# STM32U083xx register map
File version: 1.0
Registers are 32-bit, read-write, reset 0x0 unless marked. A register's access mark holds for its fields unless they carry their own. Offsets are from the block's base; [hi:lo] are bit positions; {n}, {i} and the like mark numbered series.

## LPTIM1 — LPTIMER
Base 0x40007C00
Same registers: LPTIM3 0x40009000, LPTIM2 0x40009400
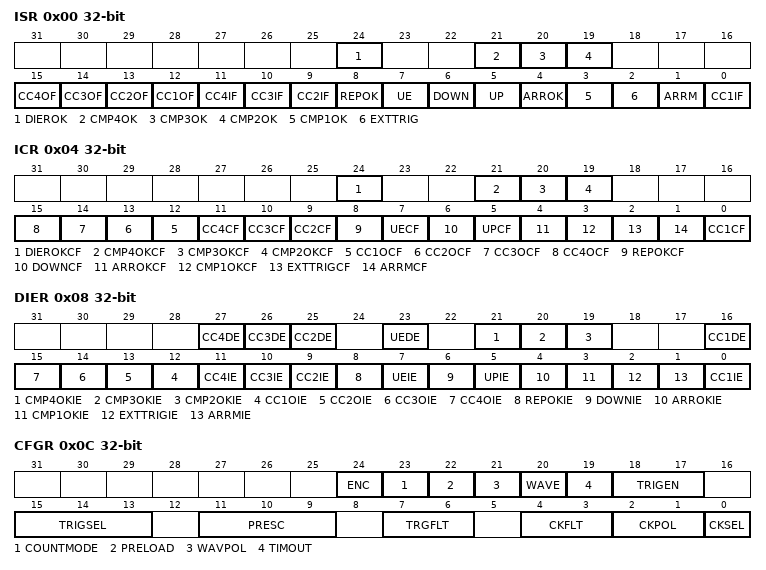
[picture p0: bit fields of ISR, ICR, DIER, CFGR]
0x00 ISR — LPTIM Interrupt and Status register
  [24] DIEROK — DMA & interrupt enable update OK
  [21] CMP4OK — Compare register 4 update OK
  [20] CMP3OK — Compare register 3 update OK
  [19] CMP2OK — Compare register 2 update OK
  [n+11] CC{n}OF (n=1..4) — Capture/Compare {n} over-capture flag
  [11] CC4IF — Capture/Compare 4 interrupt flag
  [10] CC3IF — Capture/Compare 3 interrupt flag
  [9] CC2IF — Capture/Compare 2 interrupt flag
  [8] REPOK — Repetition register update OK
  [7] UE — Update event
  [6] DOWN — Counter direction change up to down
  [5] UP — Counter direction change down to up
  [4] ARROK — Autoreload register update OK
  [3] CMP1OK — Compare register 1 update OK
  [2] EXTTRIG — External trigger edge event
  [1] ARRM — Autoreload match
  [0] CC1IF — Capture/Compare 1 interrupt flag
0x04 ICR — LPTIM Interrupt Clear register
  [24] DIEROKCF — DMA & interrupt enable update OK clear flag
  [21] CMP4OKCF — Compare register 4 update OK clear flag
  [20] CMP3OKCF — Compare register 3 update OK clear flag
  [19] CMP2OKCF — Compare register 2 update OK clear flag
  [n+11] CC{n}OCF (n=1..4) — Capture/Compare {n} over-capture clear flag
  [11] CC4CF — Capture/Compare 4 clear flag
  [10] CC3CF — Capture/Compare 3 clear flag
  [9] CC2CF — Capture/Compare 2 clear flag
  [8] REPOKCF — Repetition register update OK clear flag
  [7] UECF — Update event clear flag
  [6] DOWNCF — Counter direction change up to down clear flag
  [5] UPCF — Counter direction change down to up clear flag
  [4] ARROKCF — Autoreload register update OK clear flag
  [3] CMP1OKCF — Compare register 1 update OK clear flag
  [2] EXTTRIGCF — External trigger edge event clear flag
  [1] ARRMCF — Autoreload match clear flag
  [0] CC1CF — Capture/Compare 1 clear flag
0x08 DIER — LPTIM Interrupt Enable register
  [27] CC4DE — Capture/Compare 4 DMA request enable
  [26] CC3DE — Capture/Compare 3 DMA request enable
  [25] CC2DE — Capture/Compare 2 DMA request enable
  [23] UEDE — Update event DMA request enable
  [21] CMP4OKIE — Compare register 4 update OK interrupt enable
  [20] CMP3OKIE — Compare register 3 update OK interrupt enable
  [19] CMP2OKIE — Compare register 2 update OK interrupt enable
  [16] CC1DE — Capture/Compare 1 DMA request enable
  [n+11] CC{n}OIE (n=1..4) — Capture/Compare {n} over-capture interrupt enable
  [11] CC4IE — Capture/Compare 4 interrupt interrupt enable
  [10] CC3IE — Capture/Compare 3 interrupt interrupt enable
  [9] CC2IE — Capture/Compare 2 interrupt interrupt enable
  [8] REPOKIE — Repetition register update OK interrupt enable
  [7] UEIE — Update event interrupt enable
  [6] DOWNIE — Counter direction change up to down interrupt enable
  [5] UPIE — Counter direction change down to up interrupt enable
  [4] ARROKIE — Autoreload register update OK interrupt enable
  [3] CMP1OKIE — Compare register 1 update OK interrupt enable
  [2] EXTTRIGIE — External trigger edge event interrupt enable
  [1] ARRMIE — Autoreload match interrupt enable
  [0] CC1IE — Compare/Compare 1 interrupt enable
0x0C CFGR — LPTIM Configuration register
  [24] ENC — Encoder mode enable
  [23] COUNTMODE — Counter mode enable
    0=INTERNAL (The counter is incremented following each internal clock pulse); 1=EXTERNAL (The counter is incremented following each valid clock pulse on the LPTIM external Input1)
  [22] PRELOAD — Reg update mode
    0=IMMEDIATE (Preload is disabled: registers are updated after each APB bus write access); 1=ENDOFPERIOD (preload is enabled: registers are updated at the end of the current LPTIM period)
  [21] WAVPOL — Waveform shape
  [20] WAVE — Waveform shape
    0=PWM (LPTIM generates either a PWM waveform or a One pulse waveform depending on chosen operating mode CONTINUOUS or SINGLE); 1=SETONCE (LPTIM generates a Set Once waveform)
  [19] TIMOUT — Timout enable
  [18:17] TRIGEN — TRIGEN[1:0] bits (Trigger enable and polarity)
    1=RISING (LPTIM counter starts when a rising edge is detected); 2=FALLING (LPTIM counter starts when a falling edge is detected); 3=RISING_FALLING (LPTIM counter starts when a rising or a falling edge is detected)
  [15:13] TRIGSEL — TRIGSEL[2:0]] bits (Trigger selector)
    0=GPIO (External input trigger is connected to TIMx_ETR input); 1=RTCALARMA (External input trigger is connected to RTC Alarm A); 2=RTCALARMB (External input trigger is connected to RTC Alarm B); 3=RTCTAMP1 (External input trigger is connected to RTC Tamper 1); 4=RTCTAMP2 (External input trigger is connected to RTC Tamper 2); 5=RTCTAMP3 (External input trigger is connected to RTC Tamper 3); 6=COMP1 (External input trigger is connected to COMP1 output); 7=COMP2 (External input trigger is connected to COMP2 output)
  [11:9] PRESC — PRESC[2:0] bits (Clock prescaler)
    0=DIV1 (Prescaler division factor is set to 1); 1=DIV2 (Prescaler division factor is set to 2); 2=DIV4 (Prescaler division factor is set to 4); 3=DIV8 (Prescaler division factor is set to 8); 4=DIV16 (Prescaler division factor is set to 16); 5=DIV32 (Prescaler division factor is set to 32); 6=DIV64 (Prescaler division factor is set to 64); 7=DIV128 (Prescaler division factor is set to 128)
  [7:6] TRGFLT — TRGFLT[1:0] bits (Configurable digital filter for trigger)
    0=NONE (Any trigger active level change is considered as a valid trigger); 1=FILTER_2 (Trigger active level change must be stable for at least 2 clock periods before it is considered as valid trigger); 2=FILTER_4 (Trigger active level change must be stable for at least 4 clock periods before it is considered as valid trigger); 3=FILTER_8 (Trigger active level change must be stable for at least 8 clock periods before it is considered as valid trigger)
  [4:3] CKFLT — CKFLT[1:0] bits (Configurable digital filter for external clock)
    0=NONE (Any external clock signal level change is considered as a valid transition); 1=FILTER_2 (External clock signal level change must be stable for at least 2 clock periods before it is considered as valid transition); 2=FILTER_4 (External clock signal level change must be stable for at least 4 clock periods before it is considered as valid transition); 3=FILTER_8 (External clock signal level change must be stable for at least 8 clock periods before it is considered as valid transition)
  [2:1] CKPOL — CKPOL[1:0] bits (Clock polarity)
    0=RISING (The rising edge is the active edge used for counting); 1=FALLING (The falling edge is the active edge used for counting); 2=RISING_FALLING (Both edges are active edges)
  [0] CKSEL — Clock selector
    0=INTERNAL (LPTIM is clocked by internal clock source (APB clock or any of the embedded oscillators)); 1=EXTERNAL (LPTIM is clocked by an external clock source through the LPTIM external Input1)
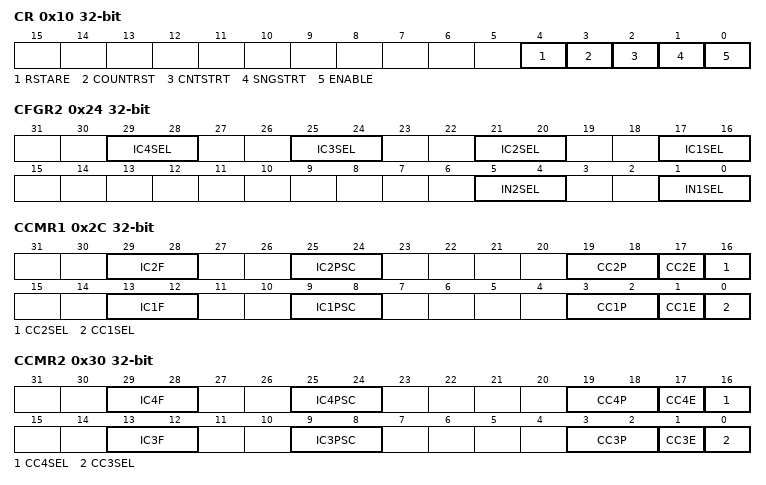
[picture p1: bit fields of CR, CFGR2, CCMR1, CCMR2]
0x10 CR — LPTIM Control register
  [4] RSTARE — Timer Counter reset after read enable (asynchronously)
  [3] COUNTRST — Timer Counter reset in synchronous mode
  [2] CNTSTRT — Timer start in continuous mode
  [1] SNGSTRT — Timer start in single mode
  [0] ENABLE — LPTIMer enable
0x14 CCR1 — LPTIM Capture/Compare register 1
  [15:0] CCR1 — Compare register 1
0x18 ARR — LPTIM Autoreload register
  [15:0] ARR — Auto reload register
0x1C CNT — LPTIM Counter register
  [15:0] CNT — Counter register
0x24 CFGR2 — LPTIM Configuration register 2
  [4n+13:4n+12] IC{n}SEL (n=1..4) — IC{n}SEL[{4n+13}:{4n+12}] bits
  [5:4] IN2SEL — IN2SEL[5:4] bits (Remap selection)
    0=GPIO (For LPTIM1 and LPTIM3); 1=COMP2 (For LPTIM1 and LPTIM3)
  [1:0] IN1SEL — IN1SEL[1:0] bits (Remap selection)
    0=GPIO (For LPTIM1, LPTIM2 and LPTIM3); 3=COMP1_COMP2 (For LPTIM2)
0x28 RCR — LPTIM Repetition register
  [7:0] REP — Repetition register value
0x2C CCMR1 — LPTIM Capture/Compare mode register 1
  [29:28] IC2F — Input capture 2 filter
  [25:24] IC2PSC — Input capture 2 prescaler
  [19:18] CC2P — Capture/Compare 2 output polarity
  [17] CC2E — Capture/Compare 2 output enable
  [16] CC2SEL — Capture/Compare 2 selection
  [13:12] IC1F — Input capture 1 filter
  [9:8] IC1PSC — Input capture 1 prescaler
  [3:2] CC1P — Capture/Compare 1 output polarity
  [1] CC1E — Capture/Compare 1 output enable
  [0] CC1SEL — Capture/Compare 1 selection
0x30 CCMR2 — LPTIM Capture/Compare mode register 2
  [29:28] IC4F — Input capture 4 filter
  [25:24] IC4PSC — Input capture 4 prescaler
  [19:18] CC4P — Capture/Compare 4 output polarity
  [17] CC4E — Capture/Compare 4 output enable
  [16] CC4SEL — Capture/Compare 4 selection
  [13:12] IC3F — Input capture 3 filter
  [9:8] IC3PSC — Input capture 3 prescaler
  [3:2] CC3P — Capture/Compare 3 output polarity
  [1] CC3E — Capture/Compare 3 output enable
  [0] CC3SEL — Capture/Compare 3 selection
{0x2C+4i} CCR{i} (i=2..4) — LPTIM Capture/Compare register {i}
  [15:0] CCR{i} — Compare register {i}
